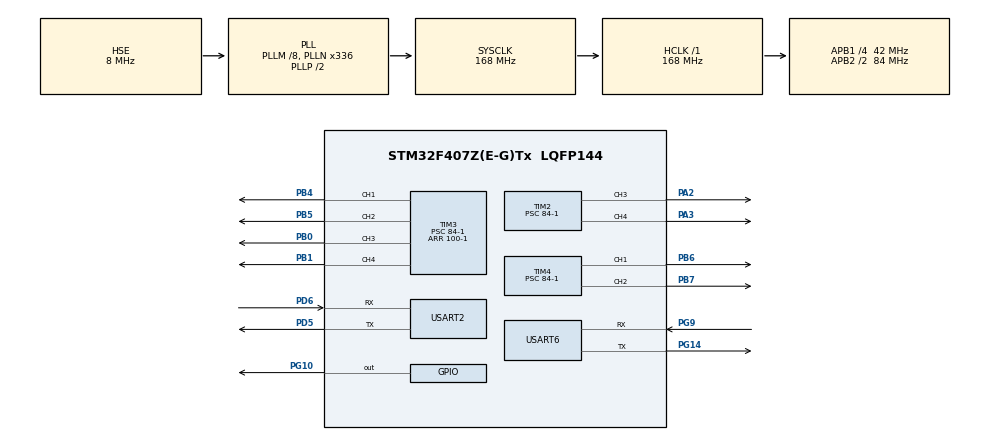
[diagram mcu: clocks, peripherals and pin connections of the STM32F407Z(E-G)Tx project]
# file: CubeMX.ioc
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Mcu.Family=STM32F4
Mcu.Name=STM32F407Z(E-G)Tx
Mcu.Package=LQFP144
NVIC.PriorityGroup=NVIC_PRIORITYGROUP_4
NVIC.TIM1_UP_TIM10_IRQn=true\:0\:0\:false\:false\:true\:true\:true
NVIC.TIM8_TRG_COM_TIM14_IRQn=true\:0\:0\:false\:false\:true\:false\:true
NVIC.TimeBase=TIM8_TRG_COM_TIM14_IRQn
NVIC.TimeBaseIP=TIM14
NVIC.USART2_IRQn=true\:0\:0\:false\:false\:true\:true\:true
NVIC.USART6_IRQn=true\:0\:0\:false\:false\:true\:true\:true
PA2.Signal=S_TIM2_CH3
PA3.Signal=S_TIM2_CH4
PB0.GPIO_Speed=GPIO_SPEED_FREQ_VERY_HIGH
PB0.Signal=S_TIM3_CH3
PB1.GPIO_Speed=GPIO_SPEED_FREQ_VERY_HIGH
PB1.Signal=S_TIM3_CH4
PB4.GPIO_Speed=GPIO_SPEED_FREQ_VERY_HIGH
PB4.Signal=S_TIM3_CH1
PB5.GPIO_Speed=GPIO_SPEED_FREQ_VERY_HIGH
PB5.Signal=S_TIM3_CH2
PB6.Signal=S_TIM4_CH1
PB7.Signal=S_TIM4_CH2
PD5.Mode=Asynchronous
PD5.Signal=USART2_TX
PD6.Mode=Asynchronous
PD6.Signal=USART2_RX
PG10.GPIO_ModeDefaultOutputPP=GPIO_MODE_OUTPUT_PP
PG10.GPIO_PuPd=GPIO_PULLDOWN
PG10.GPIO_Speed=GPIO_SPEED_FREQ_VERY_HIGH
PG10.PinState=GPIO_PIN_SET
PG10.Signal=GPIO_Output
PG14.Mode=Asynchronous
PG14.Signal=USART6_TX
PG9.Mode=Asynchronous
PG9.Signal=USART6_RX
PH0-OSC_IN.Mode=HSE-External-Oscillator
PH0-OSC_IN.Signal=RCC_OSC_IN
PH1-OSC_OUT.Mode=HSE-External-Oscillator
PH1-OSC_OUT.Signal=RCC_OSC_OUT
ProjectManager.HeapSize=0x200
ProjectManager.StackSize=0x400
ProjectManager.TargetToolchain=MDK-ARM V5
RCC.48MHZClocksFreq_Value=84000000
RCC.AHBFreq_Value=168000000
RCC.APB1CLKDivider=RCC_HCLK_DIV4
RCC.APB1Freq_Value=42000000
RCC.APB1TimFreq_Value=84000000
RCC.APB2CLKDivider=RCC_HCLK_DIV2
RCC.APB2Freq_Value=84000000
RCC.APB2TimFreq_Value=168000000
RCC.CortexFreq_Value=168000000
RCC.HCLKFreq_Value=168000000
RCC.HSE_VALUE=8000000
RCC.HSI_VALUE=16000000
RCC.LSE_VALUE=32768
RCC.PLLM=8
RCC.PLLN=336
RCC.PLLSourceVirtual=RCC_PLLSOURCE_HSE
RCC.SYSCLKFreq_VALUE=168000000
RCC.SYSCLKSource=RCC_SYSCLKSOURCE_PLLCLK
RCC.VCOOutputFreq_Value=336000000
SH.S_TIM2_CH3.0=TIM2_CH3,PWM Generation3 CH3
SH.S_TIM2_CH4.0=TIM2_CH4,PWM Generation4 CH4
SH.S_TIM3_CH1.0=TIM3_CH1,PWM Generation1 CH1
SH.S_TIM3_CH2.0=TIM3_CH2,PWM Generation2 CH2
SH.S_TIM3_CH3.0=TIM3_CH3,PWM Generation3 CH3
SH.S_TIM3_CH4.0=TIM3_CH4,PWM Generation4 CH4
SH.S_TIM4_CH1.0=TIM4_CH1,PWM Generation1 CH1
SH.S_TIM4_CH2.0=TIM4_CH2,PWM Generation2 CH2
TIM1.Period=5000-1
TIM1.Prescaler=16800-1
TIM1.TIM_MasterOutputTrigger=TIM_TRGO_RESET
TIM1.TIM_MasterSlaveMode=TIM_MASTERSLAVEMODE_DISABLE
TIM2.Channel-PWM\ Generation3\ CH3=TIM_CHANNEL_3
TIM2.Channel-PWM\ Generation4\ CH4=TIM_CHANNEL_4
TIM2.OCFastMode_PWM-PWM\ Generation3\ CH3=TIM_OCFAST_ENABLE
TIM2.OCFastMode_PWM-PWM\ Generation4\ CH4=TIM_OCFAST_ENABLE
TIM2.Period=100-1
TIM2.Prescaler=84-1
TIM3.Channel-PWM\ Generation1\ CH1=TIM_CHANNEL_1
TIM3.Channel-PWM\ Generation2\ CH2=TIM_CHANNEL_2
TIM3.Channel-PWM\ Generation3\ CH3=TIM_CHANNEL_3
TIM3.Channel-PWM\ Generation4\ CH4=TIM_CHANNEL_4
TIM3.OCFastMode_PWM-PWM\ Generation1\ CH1=TIM_OCFAST_ENABLE
TIM3.OCFastMode_PWM-PWM\ Generation2\ CH2=TIM_OCFAST_ENABLE
TIM3.OCFastMode_PWM-PWM\ Generation3\ CH3=TIM_OCFAST_ENABLE
TIM3.OCFastMode_PWM-PWM\ Generation4\ CH4=TIM_OCFAST_ENABLE
TIM3.OCMode_PWM-PWM\ Generation1\ CH1=TIM_OCMODE_PWM1
TIM3.OCPolarity_1=TIM_OCPOLARITY_HIGH
TIM3.OCPolarity_2=TIM_OCPOLARITY_HIGH
TIM3.Period=100-1
TIM3.Prescaler=84-1
TIM3.Pulse-PWM\ Generation1\ CH1=0
TIM4.Channel-PWM\ Generation1\ CH1=TIM_CHANNEL_1
TIM4.Channel-PWM\ Generation2\ CH2=TIM_CHANNEL_2
TIM4.OCFastMode_PWM-PWM\ Generation1\ CH1=TIM_OCFAST_ENABLE
TIM4.OCFastMode_PWM-PWM\ Generation2\ CH2=TIM_OCFAST_ENABLE
TIM4.Period=100-1
TIM4.Prescaler=84-1
USART2.VirtualMode=VM_ASYNC
USART6.VirtualMode=VM_ASYNC
VP_SYS_VS_tim14.Mode=TIM14
VP_TIM1_VS_ClockSourceINT.Mode=Internal
VP_TIM2_VS_ClockSourceINT.Mode=Internal
VP_TIM3_VS_ClockSourceINT.Mode=Internal
VP_TIM4_VS_ClockSourceINT.Mode=Internal
board=custom

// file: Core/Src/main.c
/* USER CODE BEGIN Header */
/**
  ******************************************************************************
  * @file           : main.c
  * @brief          : Main program body
  ******************************************************************************
  * @attention
  *
  * <h2><center>&copy; Copyright (c) 2019 STMicroelectronics.
  * All rights reserved.</center></h2>
  *
  * This software component is licensed by ST under BSD 3-Clause license,
  * the "License"; You may not use this file except in compliance with the
  * License. You may obtain a copy of the License at:
  *                        opensource.org/licenses/BSD-3-Clause
  *
  ******************************************************************************
  */
/* USER CODE END Header */

#include "main.h"

TIM_HandleTypeDef htim1;
TIM_HandleTypeDef htim2;
TIM_HandleTypeDef htim3;
TIM_HandleTypeDef htim4;

UART_HandleTypeDef huart2;
UART_HandleTypeDef huart6;

void SystemClock_Config(void);
static void MX_GPIO_Init(void);
static void MX_TIM1_Init(void);
static void MX_TIM3_Init(void);
static void MX_TIM2_Init(void);
static void MX_TIM4_Init(void);
static void MX_USART2_UART_Init(void);
static void MX_USART6_UART_Init(void);

int main(void)
{

  /* MCU Configuration--------------------------------------------------------*/

  /* Reset of all peripherals, Initializes the Flash interface and the Systick. */
  HAL_Init();

  /* Configure the system clock */
  SystemClock_Config();

  /* Initialize all configured peripherals */
  MX_GPIO_Init();
  MX_TIM1_Init();
  MX_TIM3_Init();
  MX_TIM2_Init();
  MX_TIM4_Init();
  MX_USART2_UART_Init();
  MX_USART6_UART_Init();
  /* USER CODE BEGIN 2 */

	HAL_TIM_Base_Start_IT(&htim1);
	__HAL_UART_ENABLE_IT(&huart2,UART_IT_RXNE);

	HAL_TIM_PWM_Start(&htim3,TIM_CHANNEL_1);
	HAL_TIM_PWM_Start(&htim3,TIM_CHANNEL_2);
	HAL_TIM_PWM_Start(&htim3,TIM_CHANNEL_3);
	HAL_TIM_PWM_Start(&htim3,TIM_CHANNEL_4);
	HAL_TIM_PWM_Start(&htim2,TIM_CHANNEL_3);
	HAL_TIM_PWM_Start(&htim2,TIM_CHANNEL_4);
	HAL_TIM_PWM_Start(&htim4,TIM_CHANNEL_1);
	HAL_TIM_PWM_Start(&htim4,TIM_CHANNEL_2);

	void start();
	start();
  /* USER CODE END 2 */

  /* Infinite loop */
  while (1)
  {

  }
}

void SystemClock_Config(void)
{
  RCC_OscInitTypeDef RCC_OscInitStruct = {0};
  RCC_ClkInitTypeDef RCC_ClkInitStruct = {0};

  /** Configure the main internal regulator output voltage
  */
  __HAL_RCC_PWR_CLK_ENABLE();
  __HAL_PWR_VOLTAGESCALING_CONFIG(PWR_REGULATOR_VOLTAGE_SCALE1);
  /** Initializes the CPU, AHB and APB busses clocks
  */
  RCC_OscInitStruct.OscillatorType = RCC_OSCILLATORTYPE_HSE;
  RCC_OscInitStruct.HSEState = RCC_HSE_ON;
  RCC_OscInitStruct.PLL.PLLState = RCC_PLL_ON;
  RCC_OscInitStruct.PLL.PLLSource = RCC_PLLSOURCE_HSE;
  RCC_OscInitStruct.PLL.PLLM = 8;
  RCC_OscInitStruct.PLL.PLLN = 336;
  RCC_OscInitStruct.PLL.PLLP = RCC_PLLP_DIV2;
  RCC_OscInitStruct.PLL.PLLQ = 4;
  if (HAL_RCC_OscConfig(&RCC_OscInitStruct) != HAL_OK)
  {
    Error_Handler();
  }
  /** Initializes the CPU, AHB and APB busses clocks
  */
  RCC_ClkInitStruct.ClockType = RCC_CLOCKTYPE_HCLK|RCC_CLOCKTYPE_SYSCLK
                              |RCC_CLOCKTYPE_PCLK1|RCC_CLOCKTYPE_PCLK2;
  RCC_ClkInitStruct.SYSCLKSource = RCC_SYSCLKSOURCE_PLLCLK;
  RCC_ClkInitStruct.AHBCLKDivider = RCC_SYSCLK_DIV1;
  RCC_ClkInitStruct.APB1CLKDivider = RCC_HCLK_DIV4;
  RCC_ClkInitStruct.APB2CLKDivider = RCC_HCLK_DIV2;

  if (HAL_RCC_ClockConfig(&RCC_ClkInitStruct, FLASH_LATENCY_5) != HAL_OK)
  {
    Error_Handler();
  }
}

static void MX_TIM1_Init(void)
{

  TIM_ClockConfigTypeDef sClockSourceConfig = {0};
  TIM_MasterConfigTypeDef sMasterConfig = {0};

  htim1.Instance = TIM1;
  htim1.Init.Prescaler = 16800-1;
  htim1.Init.CounterMode = TIM_COUNTERMODE_UP;
  htim1.Init.Period = 5000-1;
  htim1.Init.ClockDivision = TIM_CLOCKDIVISION_DIV1;
  htim1.Init.RepetitionCounter = 0;
  htim1.Init.AutoReloadPreload = TIM_AUTORELOAD_PRELOAD_DISABLE;
  if (HAL_TIM_Base_Init(&htim1) != HAL_OK)
  {
    Error_Handler();
  }
  sClockSourceConfig.ClockSource = TIM_CLOCKSOURCE_INTERNAL;
  if (HAL_TIM_ConfigClockSource(&htim1, &sClockSourceConfig) != HAL_OK)
  {
    Error_Handler();
  }
  sMasterConfig.MasterOutputTrigger = TIM_TRGO_RESET;
  sMasterConfig.MasterSlaveMode = TIM_MASTERSLAVEMODE_DISABLE;
  if (HAL_TIMEx_MasterConfigSynchronization(&htim1, &sMasterConfig) != HAL_OK)
  {
    Error_Handler();
  }

}

static void MX_TIM2_Init(void)
{

  TIM_ClockConfigTypeDef sClockSourceConfig = {0};
  TIM_MasterConfigTypeDef sMasterConfig = {0};
  TIM_OC_InitTypeDef sConfigOC = {0};

  htim2.Instance = TIM2;
  htim2.Init.Prescaler = 84-1;
  htim2.Init.CounterMode = TIM_COUNTERMODE_UP;
  htim2.Init.Period = 100-1;
  htim2.Init.ClockDivision = TIM_CLOCKDIVISION_DIV1;
  htim2.Init.AutoReloadPreload = TIM_AUTORELOAD_PRELOAD_DISABLE;
  if (HAL_TIM_Base_Init(&htim2) != HAL_OK)
  {
    Error_Handler();
  }
  sClockSourceConfig.ClockSource = TIM_CLOCKSOURCE_INTERNAL;
  if (HAL_TIM_ConfigClockSource(&htim2, &sClockSourceConfig) != HAL_OK)
  {
    Error_Handler();
  }
  if (HAL_TIM_PWM_Init(&htim2) != HAL_OK)
  {
    Error_Handler();
  }
  sMasterConfig.MasterOutputTrigger = TIM_TRGO_RESET;
  sMasterConfig.MasterSlaveMode = TIM_MASTERSLAVEMODE_DISABLE;
  if (HAL_TIMEx_MasterConfigSynchronization(&htim2, &sMasterConfig) != HAL_OK)
  {
    Error_Handler();
  }
  sConfigOC.OCMode = TIM_OCMODE_PWM1;
  sConfigOC.Pulse = 0;
  sConfigOC.OCPolarity = TIM_OCPOLARITY_HIGH;
  sConfigOC.OCFastMode = TIM_OCFAST_ENABLE;
  if (HAL_TIM_PWM_ConfigChannel(&htim2, &sConfigOC, TIM_CHANNEL_3) != HAL_OK)
  {
    Error_Handler();
  }
  if (HAL_TIM_PWM_ConfigChannel(&htim2, &sConfigOC, TIM_CHANNEL_4) != HAL_OK)
  {
    Error_Handler();
  }
  HAL_TIM_MspPostInit(&htim2);

}

static void MX_TIM3_Init(void)
{

  TIM_ClockConfigTypeDef sClockSourceConfig = {0};
  TIM_MasterConfigTypeDef sMasterConfig = {0};
  TIM_OC_InitTypeDef sConfigOC = {0};

  htim3.Instance = TIM3;
  htim3.Init.Prescaler = 84-1;
  htim3.Init.CounterMode = TIM_COUNTERMODE_UP;
  htim3.Init.Period = 100-1;
  htim3.Init.ClockDivision = TIM_CLOCKDIVISION_DIV1;
  htim3.Init.AutoReloadPreload = TIM_AUTORELOAD_PRELOAD_DISABLE;
  if (HAL_TIM_Base_Init(&htim3) != HAL_OK)
  {
    Error_Handler();
  }
  sClockSourceConfig.ClockSource = TIM_CLOCKSOURCE_INTERNAL;
  if (HAL_TIM_ConfigClockSource(&htim3, &sClockSourceConfig) != HAL_OK)
  {
    Error_Handler();
  }
  if (HAL_TIM_PWM_Init(&htim3) != HAL_OK)
  {
    Error_Handler();
  }
  sMasterConfig.MasterOutputTrigger = TIM_TRGO_RESET;
  sMasterConfig.MasterSlaveMode = TIM_MASTERSLAVEMODE_DISABLE;
  if (HAL_TIMEx_MasterConfigSynchronization(&htim3, &sMasterConfig) != HAL_OK)
  {
    Error_Handler();
  }
  sConfigOC.OCMode = TIM_OCMODE_PWM1;
  sConfigOC.Pulse = 0;
  sConfigOC.OCPolarity = TIM_OCPOLARITY_HIGH;
  sConfigOC.OCFastMode = TIM_OCFAST_ENABLE;
  if (HAL_TIM_PWM_ConfigChannel(&htim3, &sConfigOC, TIM_CHANNEL_1) != HAL_OK)
  {
    Error_Handler();
  }
  if (HAL_TIM_PWM_ConfigChannel(&htim3, &sConfigOC, TIM_CHANNEL_2) != HAL_OK)
  {
    Error_Handler();
  }
  if (HAL_TIM_PWM_ConfigChannel(&htim3, &sConfigOC, TIM_CHANNEL_3) != HAL_OK)
  {
    Error_Handler();
  }
  if (HAL_TIM_PWM_ConfigChannel(&htim3, &sConfigOC, TIM_CHANNEL_4) != HAL_OK)
  {
    Error_Handler();
  }
  HAL_TIM_MspPostInit(&htim3);

}

static void MX_TIM4_Init(void)
{

  TIM_ClockConfigTypeDef sClockSourceConfig = {0};
  TIM_MasterConfigTypeDef sMasterConfig = {0};
  TIM_OC_InitTypeDef sConfigOC = {0};

  htim4.Instance = TIM4;
  htim4.Init.Prescaler = 84-1;
  htim4.Init.CounterMode = TIM_COUNTERMODE_UP;
  htim4.Init.Period = 100-1;
  htim4.Init.ClockDivision = TIM_CLOCKDIVISION_DIV1;
  htim4.Init.AutoReloadPreload = TIM_AUTORELOAD_PRELOAD_DISABLE;
  if (HAL_TIM_Base_Init(&htim4) != HAL_OK)
  {
    Error_Handler();
  }
  sClockSourceConfig.ClockSource = TIM_CLOCKSOURCE_INTERNAL;
  if (HAL_TIM_ConfigClockSource(&htim4, &sClockSourceConfig) != HAL_OK)
  {
    Error_Handler();
  }
  if (HAL_TIM_PWM_Init(&htim4) != HAL_OK)
  {
    Error_Handler();
  }
  sMasterConfig.MasterOutputTrigger = TIM_TRGO_RESET;
  sMasterConfig.MasterSlaveMode = TIM_MASTERSLAVEMODE_DISABLE;
  if (HAL_TIMEx_MasterConfigSynchronization(&htim4, &sMasterConfig) != HAL_OK)
  {
    Error_Handler();
  }
  sConfigOC.OCMode = TIM_OCMODE_PWM1;
  sConfigOC.Pulse = 0;
  sConfigOC.OCPolarity = TIM_OCPOLARITY_HIGH;
  sConfigOC.OCFastMode = TIM_OCFAST_ENABLE;
  if (HAL_TIM_PWM_ConfigChannel(&htim4, &sConfigOC, TIM_CHANNEL_1) != HAL_OK)
  {
    Error_Handler();
  }
  if (HAL_TIM_PWM_ConfigChannel(&htim4, &sConfigOC, TIM_CHANNEL_2) != HAL_OK)
  {
    Error_Handler();
  }
  HAL_TIM_MspPostInit(&htim4);

}

static void MX_USART2_UART_Init(void)
{

  huart2.Instance = USART2;
  huart2.Init.BaudRate = 115200;
  huart2.Init.WordLength = UART_WORDLENGTH_8B;
  huart2.Init.StopBits = UART_STOPBITS_1;
  huart2.Init.Parity = UART_PARITY_NONE;
  huart2.Init.Mode = UART_MODE_TX_RX;
  huart2.Init.HwFlowCtl = UART_HWCONTROL_NONE;
  huart2.Init.OverSampling = UART_OVERSAMPLING_16;
  if (HAL_UART_Init(&huart2) != HAL_OK)
  {
    Error_Handler();
  }

}

static void MX_USART6_UART_Init(void)
{

  huart6.Instance = USART6;
  huart6.Init.BaudRate = 115200;
  huart6.Init.WordLength = UART_WORDLENGTH_8B;
  huart6.Init.StopBits = UART_STOPBITS_1;
  huart6.Init.Parity = UART_PARITY_NONE;
  huart6.Init.Mode = UART_MODE_TX_RX;
  huart6.Init.HwFlowCtl = UART_HWCONTROL_NONE;
  huart6.Init.OverSampling = UART_OVERSAMPLING_16;
  if (HAL_UART_Init(&huart6) != HAL_OK)
  {
    Error_Handler();
  }

}

static void MX_GPIO_Init(void)
{
  GPIO_InitTypeDef GPIO_InitStruct = {0};

  /* GPIO Ports Clock Enable */
  __HAL_RCC_GPIOH_CLK_ENABLE();
  __HAL_RCC_GPIOA_CLK_ENABLE();
  __HAL_RCC_GPIOB_CLK_ENABLE();
  __HAL_RCC_GPIOD_CLK_ENABLE();
  __HAL_RCC_GPIOG_CLK_ENABLE();

  /*Configure GPIO pin Output Level */
  HAL_GPIO_WritePin(GPIOG, GPIO_PIN_10, GPIO_PIN_SET);

  /*Configure GPIO pin : PG10 */
  GPIO_InitStruct.Pin = GPIO_PIN_10;
  GPIO_InitStruct.Mode = GPIO_MODE_OUTPUT_PP;
  GPIO_InitStruct.Pull = GPIO_PULLDOWN;
  GPIO_InitStruct.Speed = GPIO_SPEED_FREQ_VERY_HIGH;
  HAL_GPIO_Init(GPIOG, &GPIO_InitStruct);

}

void HAL_TIM_PeriodElapsedCallback(TIM_HandleTypeDef *htim)
{
  if (htim->Instance == TIM14) {
    HAL_IncTick();
  }
}

void Error_Handler(void)
{
}

/************************ (C) COPYRIGHT STMicroelectronics *****END OF FILE****/
